# STM32F756xx register map
File version: 1.0
Registers are 32-bit, read-write, reset 0x0 unless marked. A register's access mark holds for its fields unless they carry their own. Offsets are from the block's base; [hi:lo] are bit positions; {n}, {i} and the like mark numbered series; 'fields as' and 'values as' point back to an identical list.

## ETH — Ethernet MAC
Base 0x40028000
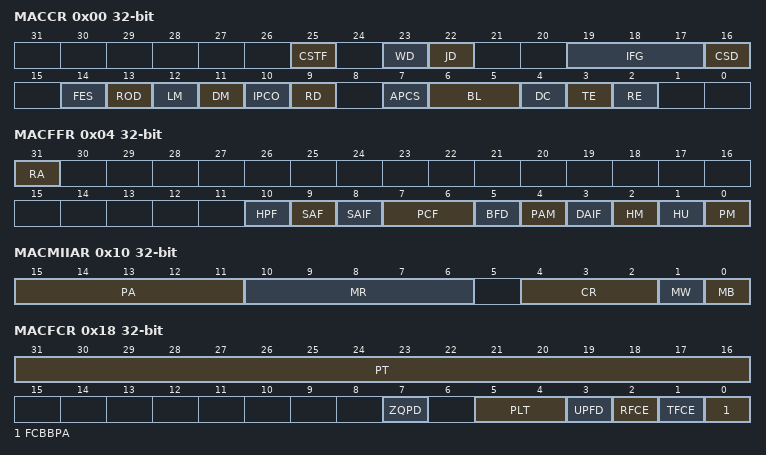
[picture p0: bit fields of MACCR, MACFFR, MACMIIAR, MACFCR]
0x00 MACCR
  [25] CSTF, [23] WD, [22] JD, [19:17] IFG, [16] CSD, [14] FES, [13] ROD, [12] LM, [11] DM, [10] IPCO, [9] RD, [7] APCS, [6:5] BL, [4] DC, [3] TE, [2] RE
0x04 MACFFR
  [31] RA, [10] HPF, [9] SAF, [8] SAIF, [7:6] PCF, [5] BFD, [4] PAM, [3] DAIF, [2] HM, [1] HU, [0] PM
0x08 MACHTHR
  [31:0] HTH
0x0C MACHTLR
  [31:0] HTL
0x10 MACMIIAR
  [15:11] PA, [10:6] MR, [4:2] CR, [1] MW, [0] MB
0x14 MACMIIDR
  [15:0] MD
0x18 MACFCR
  [31:16] PT, [7] ZQPD, [5:4] PLT, [3] UPFD, [2] RFCE, [1] TFCE, [0] FCBBPA
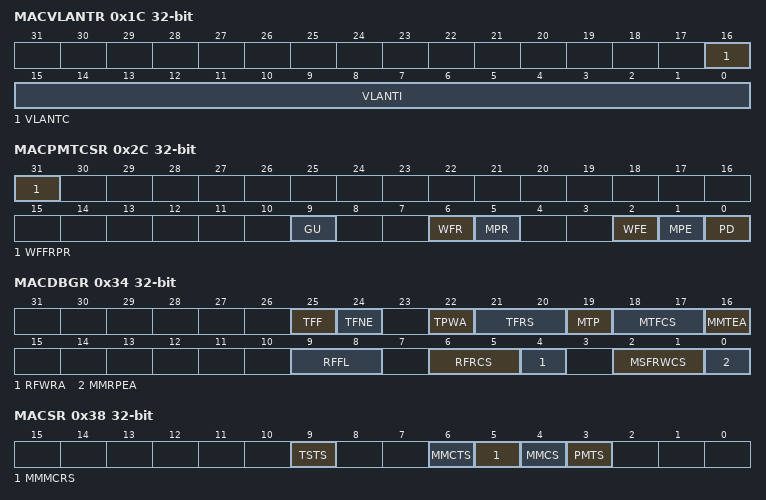
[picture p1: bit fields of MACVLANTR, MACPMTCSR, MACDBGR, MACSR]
0x1C MACVLANTR
  [16] VLANTC, [15:0] VLANTI
0x28 MACRWUFFR
  [31:0] D
0x2C MACPMTCSR
  [31] WFFRPR, [9] GU, [6] WFR, [5] MPR, [2] WFE, [1] MPE, [0] PD
0x34 MACDBGR
  [25] TFF, [24] TFNE, [22] TPWA, [21:20] TFRS, [19] MTP, [18:17] MTFCS, [16] MMTEA, [9:8] RFFL, [6:5] RFRCS, [4] RFWRA, [2:1] MSFRWCS, [0] MMRPEA
0x38 MACSR
  [9] TSTS, [6] MMCTS, [5] MMMCRS, [4] MMCS, [3] PMTS
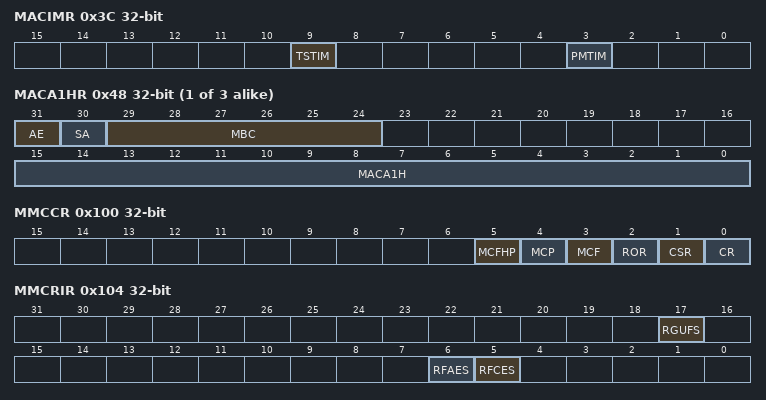
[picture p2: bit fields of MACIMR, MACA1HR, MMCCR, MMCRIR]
0x3C MACIMR
  [9] TSTIM, [3] PMTIM
0x40 MACA0HR
  [15:0] MACA0H
{0x44+8i} MACA{i}LR (i=0..3)
  [31:0] MACA{i}L
{0x40+8i} MACA{i}HR (i=1..3)
  [31] AE, [30] SA, [29:24] MBC, [15:0] MACA{i}H
0x100 MMCCR
  [5] MCFHP, [4] MCP, [3] MCF, [2] ROR, [1] CSR, [0] CR
0x104 MMCRIR
  [17] RGUFS, [6] RFAES, [5] RFCES
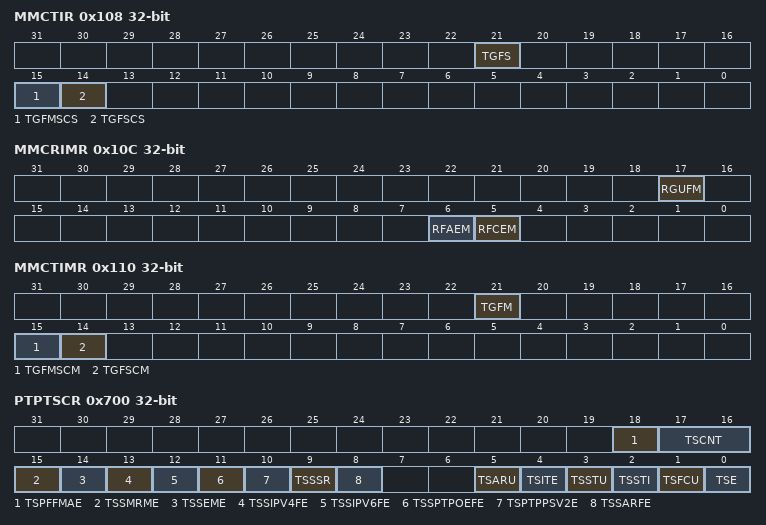
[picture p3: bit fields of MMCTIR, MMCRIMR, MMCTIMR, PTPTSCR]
0x108 MMCTIR
  [21] TGFS, [15] TGFMSCS, [14] TGFSCS
0x10C MMCRIMR
  [17] RGUFM, [6] RFAEM, [5] RFCEM
0x110 MMCTIMR
  [21] TGFM, [15] TGFMSCM, [14] TGFSCM
0x14C MMCTGFSCCR
  [31:0] TGFSCC
0x150 MMCTGFMSCCR
  [31:0] TGFMSCC
0x168 MMCTGFCR
  [31:0] TGFC
0x194 MMCRFCECR
  [31:0] RFCEC
0x198 MMCRFAECR
  [31:0] RFAEC
0x1C4 MMCRGUFCR
  [31:0] RGUFC
0x700 PTPTSCR
  [18] TSPFFMAE, [17:16] TSCNT, [15] TSSMRME, [14] TSSEME, [13] TSSIPV4FE, [12] TSSIPV6FE, [11] TSSPTPOEFE, [10] TSPTPPSV2E, [9] TSSSR, [8] TSSARFE, [5] TSARU, [4] TSITE, [3] TSSTU, [2] TSSTI, [1] TSFCU, [0] TSE
0x704 PTPSSIR
  [7:0] STSSI
0x708 PTPTSHR
  [31:0] STS
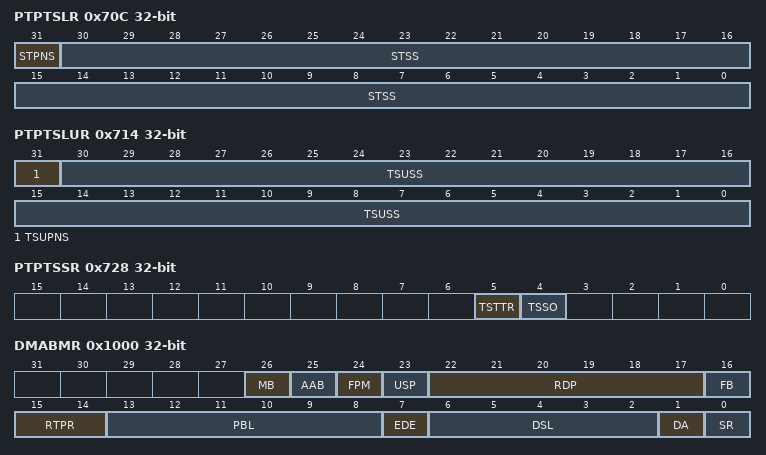
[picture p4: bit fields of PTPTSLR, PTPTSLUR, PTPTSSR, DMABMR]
0x70C PTPTSLR
  [31] STPNS, [30:0] STSS
0x710 PTPTSHUR
  [31:0] TSUS
0x714 PTPTSLUR
  [31] TSUPNS, [30:0] TSUSS
0x718 PTPTSAR
  [31:0] TSA
0x71C PTPTTHR
  [31:0] TTSH
0x720 PTPTTLR
  [31:0] TTSL
0x728 PTPTSSR
  [5] TSTTR, [4] TSSO
0x72C PTPPPSCR
  [3:0] PPSFREQ
0x1000 DMABMR
  [26] MB, [25] AAB, [24] FPM, [23] USP, [22:17] RDP, [16] FB, [15:14] RTPR, [13:8] PBL, [7] EDE, [6:2] DSL, [1] DA, [0] SR
0x1004 DMATPDR
  [31:0] TPD
0x1008 DMARPDR
  [31:0] RPD
0x100C DMARDLAR
  [31:0] SRL
0x1010 DMATDLAR
  [31:0] STL
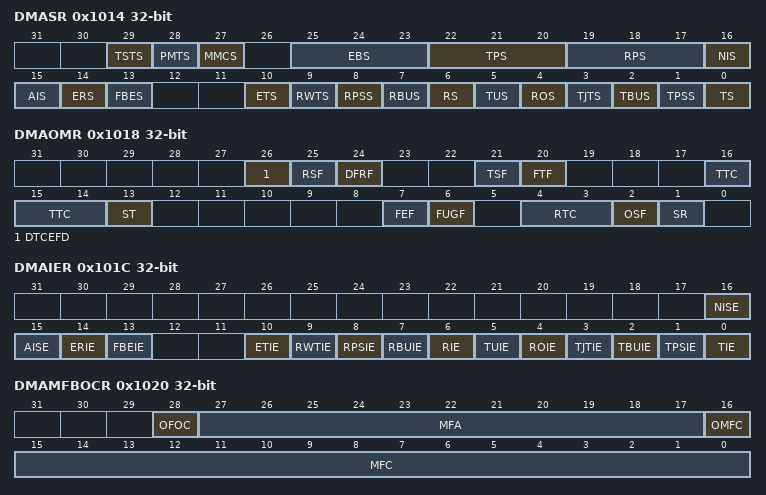
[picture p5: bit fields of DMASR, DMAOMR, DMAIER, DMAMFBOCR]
0x1014 DMASR
  [29] TSTS, [28] PMTS, [27] MMCS, [25:23] EBS, [22:20] TPS, [19:17] RPS, [16] NIS, [15] AIS, [14] ERS, [13] FBES, [10] ETS, [9] RWTS, [8] RPSS, [7] RBUS, [6] RS, [5] TUS, [4] ROS, [3] TJTS, [2] TBUS, [1] TPSS, [0] TS
0x1018 DMAOMR
  [26] DTCEFD, [25] RSF, [24] DFRF, [21] TSF, [20] FTF, [16:14] TTC, [13] ST, [7] FEF, [6] FUGF, [4:3] RTC, [2] OSF, [1] SR
0x101C DMAIER
  [16] NISE, [15] AISE, [14] ERIE, [13] FBEIE, [10] ETIE, [9] RWTIE, [8] RPSIE, [7] RBUIE, [6] RIE, [5] TUIE, [4] ROIE, [3] TJTIE, [2] TBUIE, [1] TPSIE, [0] TIE
0x1020 DMAMFBOCR
  [28] OFOC, [27:17] MFA, [16] OMFC, [15:0] MFC
0x1024 DMARSWTR
0x1048 DMACHTDR
  [31:0] HTDAP
0x104C DMACHRDR
  [31:0] HRDAP
0x1050 DMACHTBAR
  [31:0] HTBAP
0x1054 DMACHRBAR
  [31:0] HRBAP

## DMA2D — DMA2D Controller
Base 0x4002B000
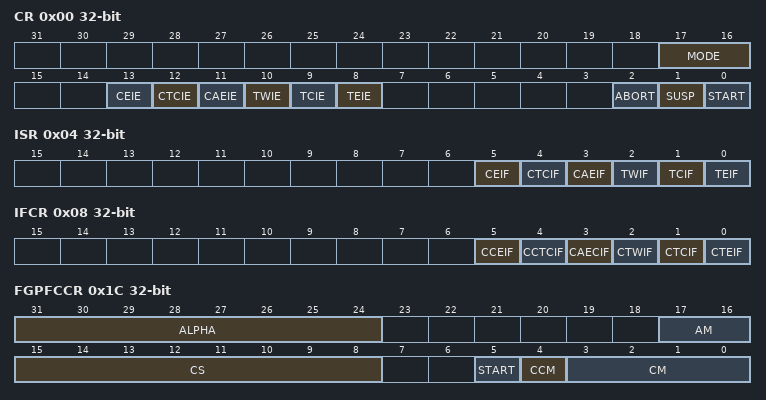
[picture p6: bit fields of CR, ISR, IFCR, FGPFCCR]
0x00 CR — DMA2D Control Register
  [17:16] MODE — DMA2D Mode[1:0]
    0=M2M (DMA2D memory to memory transfer mode); 1=M2M_PFC (DMA2D memory to memory with pixel format conversion transfer mode); 2=M2M_BLEND (DMA2D memory to memory with blending transfer mode); 3=R2M (DMA2D register to memory transfer mode)
  [13] CEIE — Configuration Error Interrupt Enable
  [12] CTCIE — CLUT Transfer Complete Interrupt Enable
  [11] CAEIE — CLUT Access Error Interrupt Enable
  [10] TWIE — Transfer Watermark Interrupt Enable
  [9] TCIE — Transfer Complete Interrupt Enable
  [8] TEIE — Transfer Error Interrupt Enable
  [2] ABORT — Abort transfer
  [1] SUSP — Suspend transfer
  [0] START — Start transfer
0x04 ISR — DMA2D Interrupt Status Register
  [5] CEIF — Configuration Error Interrupt Flag
  [4] CTCIF — CLUT Transfer Complete Interrupt Flag
  [3] CAEIF — CLUT Access Error Interrupt Flag
  [2] TWIF — Transfer Watermark Interrupt Flag
  [1] TCIF — Transfer Complete Interrupt Flag
  [0] TEIF — Transfer Error Interrupt Flag
0x08 IFCR — DMA2D Interrupt Flag Clear Register
  [5] CCEIF — Clears Configuration Error Interrupt Flag
  [4] CCTCIF — Clears CLUT Transfer Complete Interrupt Flag
  [3] CAECIF — Clears CLUT Access Error Interrupt Flag
  [2] CTWIF — Clears Transfer Watermark Interrupt Flag
  [1] CTCIF — Clears Transfer Complete Interrupt Flag
  [0] CTEIF — Clears Transfer Error Interrupt Flag
0x0C FGMAR — DMA2D Foreground Memory Address Register
  [31:0] MA — Memory Address
0x10 FGOR — DMA2D Foreground
  [13:0] LO — Line Offset
0x14 BGMAR — DMA2D Background Memory Address Register
  [31:0] MA — Memory Address
0x18 BGOR — DMA2D Background
  [13:0] LO — Line Offset
0x1C FGPFCCR — DMA2D Foreground PFC Control Register
  [31:24] ALPHA — Alpha value
  [17:16] AM — Alpha mode AM[1:0]
    0=NO_MODIF (No modification of the alpha channel value); 1=REPLACE; 2=COMBINE
  [15:8] CS — CLUT size
  [5] START
  [4] CCM — CLUT Color mode
    0=ARGB8888; 1=RGB888
  [3:0] CM — Input color mode CM[3:0]
    0=ARGB8888; 1=RGB888; 2=RGB565; 3=ARGB1555; 4=ARGB4444; 5=L8; 6=AL44; 7=AL88; 8=L4; 9=A8; 10=A4
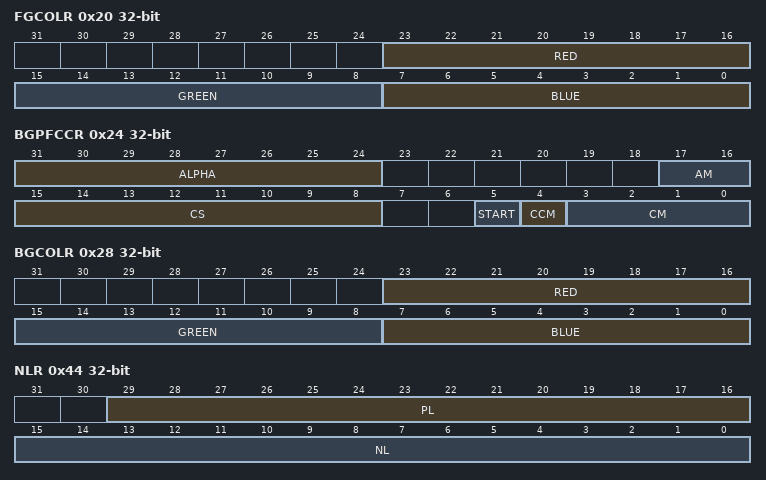
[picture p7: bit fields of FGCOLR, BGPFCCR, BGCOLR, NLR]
0x20 FGCOLR — DMA2D Foreground Color Register
  [23:16] RED — Red Value
  [15:8] GREEN — Green Value
  [7:0] BLUE — Blue Value
0x24 BGPFCCR — DMA2D Background PFC Control Register
  [31:24] ALPHA — background Input Alpha value
  [17:16] AM — Alpha mode AM[1:0]
    values as FGPFCCR.AM
  [15:8] CS — CLUT size
  [5] START
  [4] CCM — CLUT Color mode
    0=ARGB8888; 1=RGB888
  [3:0] CM — Input color mode CM[3:0]
    values as FGPFCCR.CM
0x28 BGCOLR — DMA2D Background Color Register
  fields as FGCOLR
0x2C FGCMAR — DMA2D Foreground CLUT Memory Address Register
  [31:0] MA — Memory Address
0x30 BGCMAR — DMA2D Background CLUT Memory Address Register
  [31:0] MA — Memory Address
0x34 OPFCCR — DMA2D Output PFC Control Register
  [2:0] CM — Color mode CM[2:0]
    0=ARGB8888; 1=RGB888; 2=RGB565; 3=ARGB1555; 4=ARGB4444
0x38 OCOLR — DMA2D Output Color Register
0x3C OMAR — DMA2D Output Memory Address Register
  [31:0] MA — Memory Address
0x40 OOR — DMA2D Output
  [13:0] LO — Line Offset
0x44 NLR — DMA2D Number of Line Register
  [29:16] PL — Pixel per Lines
  [15:0] NL — Number of Lines
0x48 LWR — DMA2D Line Watermark Register
  [15:0] LW — Line Watermark
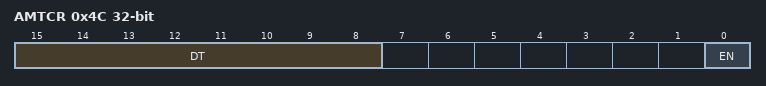
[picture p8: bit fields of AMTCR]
0x4C AMTCR — DMA2D AHB Master Timer Configuration Register
  [15:8] DT — Dead Time
  [0] EN — Enable
{0x400+4i} FGCLUT[{i}] (i=0..255)
{0x800+4i} BGCLUT[{i}] (i=0..255)
